# V3s register map
Vendor: Allwinner; Series: V3s; File version: 0.1
CPU: ARM Cortex-A7 MP1 0, little endian, MPU, no FPU, 0 interrupt priority bits
Registers are 32-bit, read-write, reset 0x0 unless marked. A register's access mark holds for its fields unless they carry their own. Offsets are from the block's base; [hi:lo] are bit positions; lines under a group give offsets from that group; {n}, {i} and the like mark numbered series.

## CE
Base 0x01C15000
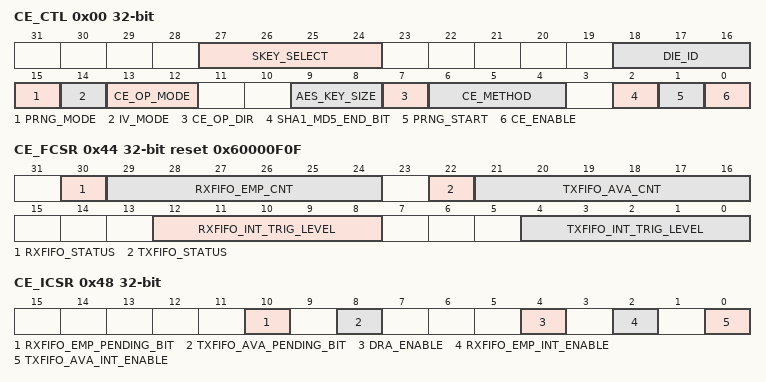
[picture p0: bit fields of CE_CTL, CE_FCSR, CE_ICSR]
0x00 CE_CTL (reset mask 0xF00F3F7) — Control Register
  [27:24] SKEY_SELECT — AES/DES/3DES key select 0: Select input CE_KEYx (Normal Mode) 1: / 2: / 3-10: Select internal Key n (n from 0 to 7) Others: Reserved
    2=_slash_ (/ 3-10: Select internal Key n (n from 0 to 7) Others: Reserved)
  [18:16] DIE_ID ro — Die Bonding ID
  [15] PRNG_MODE — PRNG generator mode 0: One-shot mode 1: Continue mode
    0=one_shot_mode; 1=Continue_mode
  [14] IV_MODE — IV Steady of SHA-1/MD5 constants 0: Constants 1: Arbitrary IV Notes: It is only used for SHA-1/MD5 engine. If the number of IV word is beyond of 4, Counter 0 register is used for IV4.
    0=Constants; 1=Arbitrary IV Notes: It is only used for SHA-1/MD5 engine. If the number of IV word is beyond of 4, Counter 0 register is used for IV4.
  [13:12] CE_OP_MODE — CE Operation Mode 00: Electronic Code Book (ECB) mode 01: Cipher Block Chaining (CBC) mode 10:/ 11: AES Ciphertext Stealing (CTS) mode
    0=Electronic Code Book (ECB) mode; 1=Cipher Block Chaining (CBC) mode 10:/; 3=AES (AES Ciphertext Stealing (CTS) mode)
  [9:8] AES_KEY_SIZE — Key Size for AES 00: 128-bits 01: 192-bits 10: 256-bits 11: Reserved
    0=_128_bits; 1=_192_bits; 2=_256_bits
  [7] CE_OP_DIR — CE Operation Direction 0: Encryption 1: Decryption
    0=Encryption; 1=Decryption
  [6:4] CE_METHOD — CE Method 000: AES 001: DES 010: Triple DES (3DES) 011: SHA-1 100: MD5 101: PRNG Others: Reserved
    0=AES; 1=DES; 2=Triple DES (3DES); 3=SHA_minus_1 (SHA-1); 4=MD5; 5=PRNG (PRNG Others: Reserved)
  [2] SHA1_MD5_END_BIT — SHA-1/MD5 Data End bit Write `1` to tell SHA-1/MD5 engine that the text data is end. If there is some data in FIFO, the engine would fetch these data and process them. After finishing message digest, this bit is clear to `0` by hardware and message digest can be read out from digest registers. Notes: It is only used for SHA-1/MD5 engine.
  [1] PRNG_START — PRNG start bit In PRNG one-shot mode, write `1` to start PRNG. After generating one group random data (5 words), this bit is clear to `0` by hardware.
  [0] CE_ENABLE — CE Enable A disable on this bit overrides any other block and flushes all FIFOs. 0: Disable 1: Enable
    0=Disable; 1=Enable
{0x4+4i} CE_KEY_n_[{i}] (i=0..7) — CE_KEY_n_[{i}]
  [31:0] CE_KEY — Key[n] Input Value (n= 0~7)/ PRNG Seed[n] (n= 0~5)
{0x24+4i} _n[{i}] (i=0..3) group
  0x00 CE_IV_n_
    [31:0] CE_IV_VALUE — Initialization Vector (IV[n]) Input Value (n= 0~3)
  0x10 CE_CNT_n_
    [31:0] CE_CNT_VALUE — Counter Input Value (n= 0~3)
0x44 CE_FCSR reset 0x60000F0F
  [30] RXFIFO_STATUS ro — RX FIFO Empty 0: No room for new word in RX FIFO 1: More than one room for new word in RX FIFO (>= 1 word)
    0=No room for new word in RX FIFO; 1=More than one room for new word in RX FIFO (>= 1 word)
  [29:24] RXFIFO_EMP_CNT ro — RX FIFO Empty Space Word Counter
  [22] TXFIFO_STATUS ro — TX FIFO Data Available Flag 0: No available data in TX FIFO 1: More than one data in TX FIFO (>= 1 word)
    0=No available data in TX FIFO; 1=More than one data in TX FIFO (>= 1 word)
  [21:16] TXFIFO_AVA_CNT ro — TX FIFO Available Word Counter
  [12:8] RXFIFO_INT_TRIG_LEVEL — RX FIFO Empty Trigger Level Interrupt and DMA request trigger level for RXFIFO normal condition Trigger Level = RXTL + 1 Notes: RX FIFO is used for input the data.
  [4:0] TXFIFO_INT_TRIG_LEVEL — TX FIFO Trigger Level Interrupt and DMA request trigger level for TXFIFO normal condition Trigger Level = TXTL + 1 Notes: TX FIFO is used for output the result data.
0x48 CE_ICSR
  [10] RXFIFO_EMP_PENDING_BIT — RX FIFO Empty Pending bit 0: No pending 1: RX FIFO Empty pending Notes: Write `1` to clear or automatic clear if interrupt condition fails.
    0=No_pending; 1=RX (RX FIFO Empty pending Notes: Write `1` to clear or automatic clear if interrupt condition fails.)
  [8] TXFIFO_AVA_PENDING_BIT — TX FIFO Data Available Pending bit 0: No TX FIFO pending 1: TX FIFO pending Notes: Write `1` to clear or automatic clear if interrupt condition fails.
    0=No TX FIFO pending; 1=TX (TX FIFO pending Notes: Write `1` to clear or automatic clear if interrupt condition fails.)
  [4] DRA_ENABLE — DRQ Enable 0: Disable DRQ (CPU polling mode) 1: Enable DRQ (DMA mode)
    0=Disable DRQ (CPU polling mode); 1=Enable DRQ (DMA mode)
  [2] RXFIFO_EMP_INT_ENABLE — RX FIFO Empty Interrupt Enable 0: Disable 1: Enable Notes: If it is set to `1`, when the number of empty room is great or equal (>=) the preset threshold, the interrupt is trigger and the correspond flag is set.
    0=Disable; 1=Enable Notes: If it is set to `1`, when the number of empty room is great or equal (>=) the preset threshold, the interrupt is trigger and the correspond flag is set
  [0] TXFIFO_AVA_INT_ENABLE — TX FIFO Data Available Interrupt Enable 0: Disable 1: Enable Notes: If it is set to `1`, when available data number is great or equal (>=) the preset threshold, the interrupt is trigger and the correspond flag is set.
    0=Disable; 1=Enable Notes: If it is set to `1`, when available data number is great or equal (>=) the preset threshold, the interrupt is trigger and the correspond flag is set
{0x4C+4i} CE_MD_n_[{i}] (i=0..4) — CE_MD_n_[{i}]
  [31:0] CE_MID_DATA ro — SHA1/ MD5 Message digest MD[n] for SHA1/MD5 (n= 0~4)
0x60 CE_CTS_LEN
  [31:0] AES_CTS — ciphertext length in byte unit The value of `0` means no data.
0x200 CE_RX
  [31:0] CE_RX_FIFO wo — 32-bits RX FIFO for Input
0x204 CE_TX
  [31:0] CE_RX_FIFO wo — 32-bits TX FIFO for Output
